# CEC1712H_S2_SX register map
Vendor: Microchip Technology; Series: CEC1712H_S2_SX; File version: 0
CPU: CM4 r1p0, little endian, no MPU, 3 interrupt priority bits, 172 interrupts
Registers are 32-bit, read-write, reset 0x0 unless marked. A register's access mark holds for its fields unless they carry their own. Offsets are from the block's base; [hi:lo] are bit positions; {n}, {i} and the like mark numbered series.

## ADC — This block is designed to convert external analog voltage readings into digital values.
Base 0x40007C00; register names take the prefix ADC_
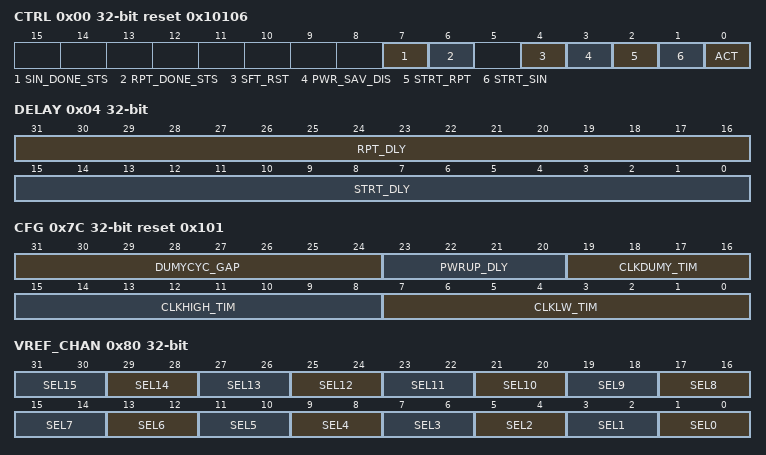
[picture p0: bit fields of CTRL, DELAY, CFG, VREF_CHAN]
0x00 CTRL reset 0x10106 — The ADC Control Register is used to control the behavior of the Analog to Digital Converter.
  [7] SIN_DONE_STS — 0: ADC single-sample conversion is not complete. 1: ADC single-sample conversion is completed. (R/WC)
  [6] RPT_DONE_STS — 0: ADC repeat-sample conversion is not complete. 1: ADC repeat-sample conversion is completed. (R/WC)
  [4] SFT_RST — (SOFT_RESET) 1: writing one causes a reset of the ADC block hardware (not the registers) 0: writing zero takes the ADC block out of reset
  [3] PWR_SAV_DIS — 0: Power saving feature is enabled. 1: Power saving feature is disabled.
  [2] STRT_RPT — 0: The ADC Repeat Mode is disabled. 1: The ADC Repeat Mode is enabled.
  [1] STRT_SIN — (START_SINGLE) 0: The ADC Single Mode is disabled. 1: The ADC Single Mode is enabled. Note: This bit is self-clearing
  [0] ACT — 0: The ADC is disabled and placed in its lowest power state. 1: ADC block is enabled for operation.
0x04 DELAY — The ADC Delay register determines the delay from setting Start_Repeat in the ADC Control Register and the start of a conversion cycle. This register also controls the interval between conversion cycles in repeat mode.
  [31:16] RPT_DLY — This field determines the interval between conversion cycles when Start_Repeat is 1.
  [15:0] STRT_DLY — This field determines the starting delay before a conversion cycle is begun when Start_Repeat is written with a 1.
0x08 CHAN_STS — The ADC Status Register indicates whether the ADC has completed a conversion cycle. All bits are cleared by being written with a 1. 0: conversion of the corresponding ADC channel is not complete. 1: conversion of the corresponding ADC channel is complete
  [15:0] STS — All bits are cleared by being written with a '1'. 1=conversion of the corresponding ADC channel is complete; 0=conversion of the corresponding ADC channel is not complete. For enabled single cycles, the SINGLE_DONE_STATUS bit in the. ADC Control Register is also set after all enabled channel conversion are done; for enabled repeat cycles, the REPEAT_DONE_STATUS in the ADC Control Register is also set after all enabled channel conversion are done.
0x0C SNG_EN — The ADC Single Register is used to control which ADC channel is captured during a Single-Sample conversion cycle initiated by the Start_Single bit in the ADC Control Register. APPLICATION NOTE: Do not change the bits in this register in the middle of a conversion cycle to insure proper operation. 0: single cycle conversions for this channel are disabled. 1: single cycle conversions for this channel are enabled
  [15:0] S_EN — Each bit in this field enables the corresponding ADC channel when a single cycle of conversions is started when the. START_SINGLE bit in the ADC Control Register is written with a 1. 1=single cycle conversions for this channel are enabled. 0=single cycle conversions for this channel are disabled. Note: If this register is changed while a conversion.
0x10 REPT_EN — The ADC Repeat Register is used to control which ADC channels are captured during a repeat conversion cycle initiated by the Start_Repeat bit in the ADC Control Register.
  [15:0] R_EN — Each bit in this field enables the corresponding ADC channel for each pass of the Repeated ADC Conversion that is controlled by bit START_REPEAT in the ADC Control Register. 1=repeat conversions for this channel are enabled; 0=repeat conversions for this channel are disabled
{0x14+4i} CHAN_RD[{i}] (i=0..15) — All 16 ADC channels return their results into a 32-bit reading register. In each case the low 10 bits of the reading register return the result of the Analog to Digital conversion and the upper 22 bits return 0.
0x7C CFG reset 0x101 — The ADC Configuration Register is used to configure the ADC clock timing.
  [31:24] DUMYCYC_GAP — These bits define the number of micro-seconds between consective Starts.
  [23:20] PWRUP_DLY — These bits define the power up delay in number of micro-seconds. Valid Values are from 0x0 to 0xF.
  [19:16] CLKDUMY_TIM — These bits define the dummy cycles of the ADC clock. Valid Values are from 0x0 to 0xF.
  [15:8] CLKHIGH_TIM — These bits define the high time count of the ADC clock. 0= not used. 1= 1 System Clock. 2= 2 System Clock.
  [7:0] CLKLW_TIM — These bits define the low time count of the ADC clock. 0= not used. 1= 1 System Clock. 2= 2 System Clock.
0x80 VREF_CHAN — The ADC Channel Register is used to configure the reference voltage to the clock timing.
  [2n+1:2n] SEL{n} (n=0..15) — These bits define the reference voltage for Channel {n}. 0h= VREF0. 1h= VREF1. 2h= Reserved. 3h= Reserved
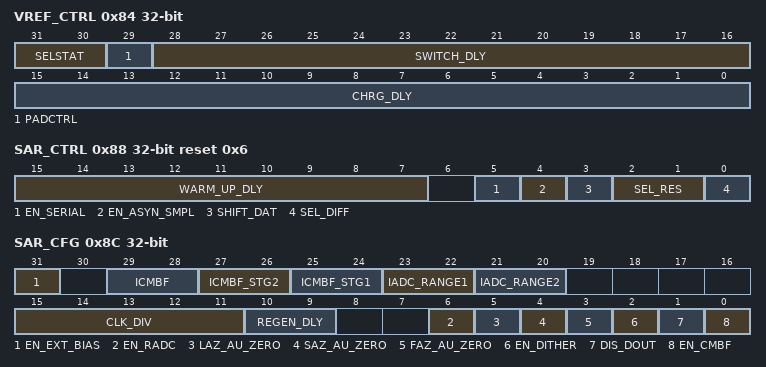
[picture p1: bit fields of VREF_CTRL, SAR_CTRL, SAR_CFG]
0x84 VREF_CTRL — This is the VREF Control Register
  [31:30] SELSTAT — This fields gives information about the current VREF selected. 0x0= VREF0. 0x1= VREF1. 0x2= Reserved. 0x3= Reserved
  [29] PADCTRL — This fields give the choice to the application whether to float the unused PAD's or to Drive them to 0. 1= Drive unused PAD's Low 0b. 0= Leave unused PAD's Floating.
  [28:16] SWITCH_DLY — This field represnts the delay time interval between switching VREF Selects.
  [15:0] CHRG_DLY — This field represnts the delay time to charge up the external VREF capacitor.
0x88 SAR_CTRL reset 0x6 — This is the SAR ADC Control Register.
  [15:7] WARM_UP_DLY — This field represents the warmup delay number in microseconds.
  [5] EN_SERIAL — This field enables serial output (dout) from ADC. 0= Parallel dout. 1= Serial dout.
  [4] EN_ASYN_SMPL — This field enables asynchronous sampling. 0= Async Sampling Disabled. 1= Async Sampling Enabled.
  [3] SHIFT_DAT — This field defined if the ADC output is Right or Left Justified. 1= adc_dout is not shifted and lower bits are set to 0. 0= adc_dout is shifted right following resolution selected.
  [2:1] SEL_RES — This field select the ADC Resolution (10/12 bits). 0x0= Reserved. 0x1= Reserved. 0x2= 10 bit ADC resolution. 0x3= 12 bit ADC resolution.
  [0] SEL_DIFF — This field select between Single ended / Differential input. 0= ADC core is enabled for single ended input operation. 1= ADC core is enabled for differential input operation.
0x8C SAR_CFG — This is the SAR ADC Configuration Register.
  [31] EN_EXT_BIAS — EN external bias. 1 = Disables internal switched cap bias circuit. 0 = Enables internal switched cap bias circuit.
  [29:28] ICMBF — This register controls the bias current for common mode buffer amplifier.
  [27:26] ICMBF_STG2 — This register controls the bias current for the 2nd stage of the comparator.
  [25:24] ICMBF_STG1 — This register controls the bias current for the 1st stage of the comparator.
  [23:22] IADC_RANGE1 — This register controls the current consumption for the whole ADC.
  [21:20] IADC_RANGE2 — This register controls the current consumption for the whole ADC.
  [15:11] CLK_DIV — This register defines the programmable ADC Clock divider value. Divider ratios of 256,128,64,32,16 are supported.
  [10:9] REGEN_DLY — This register defines the delay between regen and latch.
  [6] EN_RADC — Enable RADC. 1 = RDAC remains high during power cycling. 0 = Controls RDAC during power cycling.
  [5] LAZ_AU_ZERO — Enable L_AZ AUTOZEROING. 1= Disable L_AZ autozeroing. 0= Enable L_AZ autozeroing.
  [4] SAZ_AU_ZERO — Enable S_AZ AUTOZEROING. 1= Disable S_AZ autozeroing. 0= Enable S_AZ autozeroing.
  [3] FAZ_AU_ZERO — Enable F_AZ AUTOZEROING. 1= Disable f_az autozeroing. 0= Enable f_az autozeroing.
  [2] EN_DITHER — Enable Dithering. 0= Disable Dither. 1= Enable Dither.
  [1] DIS_DOUT — Disable Parallel Output. 0= Enable Parallel Output. 1= Disable Parallel Output.
  [0] EN_CMBF — Enable Common Mode Buffer Amplifier. 0= Common Mode Buffer Amplifier is high all the time. 1= Controls Common Mode Buffer Amplifier during power cycling.

## Notices in the file
Copyright (c) 2023 Microchip Technology Inc.
SPDX-License-Identifier: Apache-2.0
Licensed under the Apache License, Version 2.0 (the "License");
you may not use this file except in compliance with the License.
You may obtain a copy of the License at
http://www.apache.org/licenses/LICENSE-2.0
Unless required by applicable law or agreed to in writing, software
distributed under the License is distributed on an "AS IS" BASIS,
WITHOUT WARRANTIES OR CONDITIONS OF ANY KIND, either express or implied.
See the License for the specific language governing permissions and
limitations under the License.
